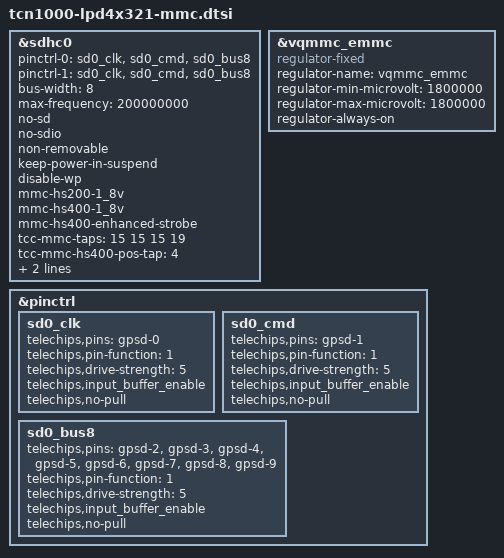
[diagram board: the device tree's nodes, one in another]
// SPDX-License-Identifier: (GPL-2.0-or-later OR MIT)
/*
 * Copyright (C) 2023 Telechips Inc.
 */

/* eMMC */
&sdhc0 {
	pinctrl-names = "default", "sleep";
	pinctrl-0 = <&sd0_clk &sd0_cmd &sd0_bus8>;
	pinctrl-1 = <&sd0_clk &sd0_cmd &sd0_bus8>;
	status = "okay";
	bus-width = <8>;
	max-frequency = <200000000>;

	no-sd;
	no-sdio;
	non-removable;
	keep-power-in-suspend;
	disable-wp;

	mmc-hs200-1_8v;
	mmc-hs400-1_8v;
	mmc-hs400-enhanced-strobe;

	tcc-mmc-taps = <15 15 15 19>;
	tcc-mmc-hs400-pos-tap = <4>;
	tcc-mmc-hs400-neg-tap = <10>;

	vqmmc-supply = <&vqmmc_emmc>;
};

&vqmmc_emmc {
	compatible = "regulator-fixed";
	regulator-name = "vqmmc_emmc";
	regulator-min-microvolt = <1800000>;
	regulator-max-microvolt = <1800000>;
	regulator-always-on;
};

/* GPIO */
&pinctrl {
	sd0_clk: sd0_clk {
		telechips,pins = "gpsd-0";
		telechips,pin-function = <1>;
		telechips,drive-strength = <5>;
		telechips,input_buffer_enable;
		telechips,no-pull;
	};

	sd0_cmd: sd0_cmd {
		telechips,pins = "gpsd-1";
		telechips,pin-function = <1>;
		telechips,drive-strength = <5>;
		telechips,input_buffer_enable;
		telechips,no-pull;
	};

	sd0_bus8: sd0_bus8 {
		telechips,pins = "gpsd-2", "gpsd-3", "gpsd-4", "gpsd-5",
		                 "gpsd-6", "gpsd-7", "gpsd-8", "gpsd-9";
		telechips,pin-function = <1>;
		telechips,drive-strength = <5>;
		telechips,input_buffer_enable;
		telechips,no-pull;
	};
};
